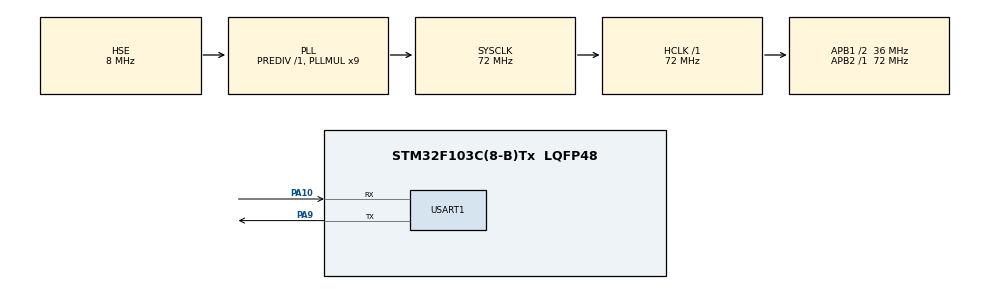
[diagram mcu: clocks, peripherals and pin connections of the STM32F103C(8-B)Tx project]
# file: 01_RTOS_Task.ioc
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FREERTOS.Tasks01=Task01,0,128,StartTask01,Default,NULL,Dynamic,NULL,NULL
Mcu.Family=STM32F1
Mcu.Name=STM32F103C(8-B)Tx
Mcu.Package=LQFP48
NVIC.PriorityGroup=NVIC_PRIORITYGROUP_4
NVIC.TIM4_IRQn=true\:15\:0\:false\:false\:true\:false\:false\:true\:true
NVIC.TimeBase=TIM4_IRQn
NVIC.TimeBaseIP=TIM4
PA10.Mode=Asynchronous
PA10.Signal=USART1_RX
PA13.Mode=Serial_Wire
PA13.Signal=SYS_JTMS-SWDIO
PA14.Mode=Serial_Wire
PA14.Signal=SYS_JTCK-SWCLK
PA9.Mode=Asynchronous
PA9.Signal=USART1_TX
PD0-OSC_IN.Mode=HSE-External-Oscillator
PD0-OSC_IN.Signal=RCC_OSC_IN
PD1-OSC_OUT.Mode=HSE-External-Oscillator
PD1-OSC_OUT.Signal=RCC_OSC_OUT
ProjectManager.HeapSize=0x200
ProjectManager.StackSize=0x400
ProjectManager.TargetToolchain=MDK-ARM V5.32
RCC.AHBFreq_Value=72000000
RCC.APB1CLKDivider=RCC_HCLK_DIV2
RCC.APB1Freq_Value=36000000
RCC.APB1TimFreq_Value=72000000
RCC.APB2Freq_Value=72000000
RCC.APB2TimFreq_Value=72000000
RCC.HCLKFreq_Value=72000000
RCC.PLLMUL=RCC_PLL_MUL9
RCC.PLLSourceVirtual=RCC_PLLSOURCE_HSE
RCC.SYSCLKFreq_VALUE=72000000
RCC.SYSCLKSource=RCC_SYSCLKSOURCE_PLLCLK
RCC.USBFreq_Value=72000000
USART1.VirtualMode=VM_ASYNC
VP_FREERTOS_VS_CMSIS_V1.Mode=CMSIS_V1
VP_SYS_VS_tim4.Mode=TIM4
board=custom

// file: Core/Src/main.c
/* USER CODE BEGIN Header */
/**
  ******************************************************************************
  * @file           : main.c
  * @brief          : Main program body
  ******************************************************************************
  * @attention
  *
  * Copyright (c) 2025 STMicroelectronics.
  * All rights reserved.
  *
  * This software is licensed under terms that can be found in the LICENSE file
  * in the root directory of this software component.
  * If no LICENSE file comes with this software, it is provided AS-IS.
  *
  ******************************************************************************
  */
/* USER CODE END Header */
#include "main.h"
#include "cmsis_os.h"

/* USER CODE BEGIN Includes */
#include <math.h>
#include <stdarg.h>
#include <stdio.h>
/* USER CODE END Includes */

UART_HandleTypeDef huart1;

osThreadId Task01Handle;
/* USER CODE BEGIN PV */

osThreadId Task02Handle;

#define EVENT0	(1UL << 0)
#define EVENT1	(1UL << 1)
#define EVENT2	(1UL << 2)

EventGroupHandle_t eventGroupHandle;
EventBits_t EventB;

/* USER CODE END PV */

void SystemClock_Config(void);
static void MX_GPIO_Init(void);
static void MX_USART1_UART_Init(void);
void StartTask01(void const * argument);
void StartTask02(void const * argument);

/* USER CODE BEGIN 0 */
char buff[40];
void mPrint(const char*format ,...) {
    va_list args;
    va_start(args, format);
    int len = vsnprintf(buff, sizeof(buff), format, args);
    va_end(args);
    // UART
		HAL_UART_Transmit(&huart1, (uint8_t*)buff, len, 1000);
}
/* USER CODE END 0 */

int main(void)
{

  /* MCU Configuration--------------------------------------------------------*/

  /* Reset of all peripherals, Initializes the Flash interface and the Systick. */
  HAL_Init();

  /* Configure the system clock */
  SystemClock_Config();

  /* Initialize all configured peripherals */
  MX_GPIO_Init();
  MX_USART1_UART_Init();

  /* Create the thread(s) */
  /* definition and creation of Task01 */
  osThreadDef(Task01, StartTask01, 3, 0, 128);
  Task01Handle = osThreadCreate(osThread(Task01), NULL);

  /* USER CODE BEGIN RTOS_THREADS */
	osThreadDef(Task02, StartTask02, 2, 0, 128);
  Task02Handle = osThreadCreate(osThread(Task02), NULL);
  /* add threads, ... */
  /* USER CODE END RTOS_THREADS */

  /* Start scheduler */
  osKernelStart();

  /* We should never get here as control is now taken by the scheduler */

  /* Infinite loop */
  while (1)
  {

  }
}

void SystemClock_Config(void)
{
  RCC_OscInitTypeDef RCC_OscInitStruct = {0};
  RCC_ClkInitTypeDef RCC_ClkInitStruct = {0};

  /** Initializes the RCC Oscillators according to the specified parameters
  * in the RCC_OscInitTypeDef structure.
  */
  RCC_OscInitStruct.OscillatorType = RCC_OSCILLATORTYPE_HSE;
  RCC_OscInitStruct.HSEState = RCC_HSE_ON;
  RCC_OscInitStruct.HSEPredivValue = RCC_HSE_PREDIV_DIV1;
  RCC_OscInitStruct.HSIState = RCC_HSI_ON;
  RCC_OscInitStruct.PLL.PLLState = RCC_PLL_ON;
  RCC_OscInitStruct.PLL.PLLSource = RCC_PLLSOURCE_HSE;
  RCC_OscInitStruct.PLL.PLLMUL = RCC_PLL_MUL9;
  if (HAL_RCC_OscConfig(&RCC_OscInitStruct) != HAL_OK)
  {
    Error_Handler();
  }

  /** Initializes the CPU, AHB and APB buses clocks
  */
  RCC_ClkInitStruct.ClockType = RCC_CLOCKTYPE_HCLK|RCC_CLOCKTYPE_SYSCLK
                              |RCC_CLOCKTYPE_PCLK1|RCC_CLOCKTYPE_PCLK2;
  RCC_ClkInitStruct.SYSCLKSource = RCC_SYSCLKSOURCE_PLLCLK;
  RCC_ClkInitStruct.AHBCLKDivider = RCC_SYSCLK_DIV1;
  RCC_ClkInitStruct.APB1CLKDivider = RCC_HCLK_DIV2;
  RCC_ClkInitStruct.APB2CLKDivider = RCC_HCLK_DIV1;

  if (HAL_RCC_ClockConfig(&RCC_ClkInitStruct, FLASH_LATENCY_2) != HAL_OK)
  {
    Error_Handler();
  }
}

static void MX_USART1_UART_Init(void)
{

  huart1.Instance = USART1;
  huart1.Init.BaudRate = 115200;
  huart1.Init.WordLength = UART_WORDLENGTH_8B;
  huart1.Init.StopBits = UART_STOPBITS_1;
  huart1.Init.Parity = UART_PARITY_NONE;
  huart1.Init.Mode = UART_MODE_TX_RX;
  huart1.Init.HwFlowCtl = UART_HWCONTROL_NONE;
  huart1.Init.OverSampling = UART_OVERSAMPLING_16;
  if (HAL_UART_Init(&huart1) != HAL_OK)
  {
    Error_Handler();
  }

}

static void MX_GPIO_Init(void)
{

  /* GPIO Ports Clock Enable */
  __HAL_RCC_GPIOD_CLK_ENABLE();
  __HAL_RCC_GPIOA_CLK_ENABLE();

}

/* USER CODE BEGIN 4 */

eTaskState state1;
eTaskState state2;

uint16_t cnt = 0;
uint16_t test = 0;

void StartTask02(void const * argument)
{
  /* USER CODE BEGIN 5 */
  /* Infinite loop */
	while(1)
	{
		mPrint("Task 2 is running\n");
		test = cnt % 3; // 0 1 2
		switch(test)
		{
			case 0:
				xEventGroupSetBits(eventGroupHandle, EVENT0);
				break;

			case 1:
				xEventGroupSetBits(eventGroupHandle, EVENT1);
				break;

			case 2:
				xEventGroupSetBits(eventGroupHandle, EVENT2);
				break;

			default:
				break;
		}
		cnt++;
		osDelay(1000);
	}

//  for(;;)
//  {
//		mPrint("Task2\n");
//		state1 = eTaskGetState((TaskHandle_t)Task01Handle);
//		state2 = eTaskGetState((TaskHandle_t)Task02Handle);
//		mPrint("State Task1: %d\n", state1);
//		mPrint("State Task2: %d\n", state2);
//    osDelay(1000);
//  }
  /* USER CODE END 5 */
}
/* USER CODE END 4 */

void StartTask01(void const * argument)
{
  /* USER CODE BEGIN 5 */
  /* Infinite loop */

	eventGroupHandle = xEventGroupCreate();

	while(1)
	{
		mPrint("Task 1 is running\n");
		EventB = xEventGroupWaitBits(eventGroupHandle, EVENT0|EVENT1|EVENT2, pdTRUE, pdTRUE|pdFALSE, osWaitForever);
		if((EventB & EVENT0) != 0)
		{
			mPrint("Event 0\r\n");
		}
		if((EventB & EVENT1) != 0)
		{
			mPrint("Event 1\r\n");
		}
		if((EventB & EVENT2) != 0)
		{
			mPrint("Event 2\r\n");
		}
		osDelay(1000);
	}

		// Code for Task
//  for(;;)
//  {
//    mPrint("Task1\n");
//		osDelay(10000);
//  }
  /* USER CODE END 5 */
}

void HAL_TIM_PeriodElapsedCallback(TIM_HandleTypeDef *htim)
{
  if (htim->Instance == TIM4) {
    HAL_IncTick();
  }
}

void Error_Handler(void)
{
  __disable_irq();
  while (1)
  {
  }
}
